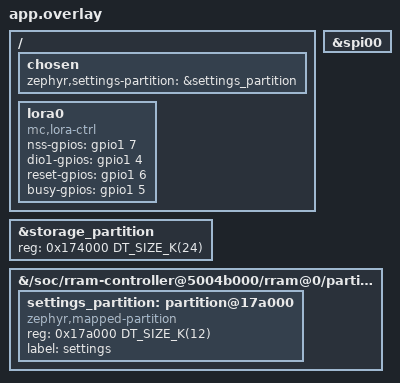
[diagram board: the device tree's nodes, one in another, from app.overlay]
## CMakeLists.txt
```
# Step 4e — full MeshCore companion (companion_radio MyMesh) on the Zephyr seams.
cmake_minimum_required(VERSION 3.20.0)
find_package(Zephyr REQUIRED HINTS $ENV{ZEPHYR_BASE})
project(mc_zephyr_companion)

get_filename_component(MC_ROOT "${CMAKE_CURRENT_SOURCE_DIR}/../.." ABSOLUTE)
set(CR       "${MC_ROOT}/examples/companion_radio")
set(ALFS     "${MC_ROOT}/arch/stm32/Adafruit_LittleFS_stm32/src")
set(RADIOLIB "$ENV{HOME}/Arduino/libraries/RadioLib/src")
set(CRYPTO   "$ENV{HOME}/Arduino/libraries/Crypto/src")
set(CAYENNE  "$ENV{HOME}/Arduino/libraries/CayenneLPP/src")
set(BASE64   "$ENV{HOME}/Arduino/libraries/base64/src")
set(RTCLIB   "$ENV{HOME}/Arduino/libraries/RTClib/src")
set(AJSON    "$ENV{HOME}/Arduino/libraries/ArduinoJson/src")
set(ED25519  "${MC_ROOT}/lib/ed25519")

# MeshCore core + helper set (mirrors the Arduino companion curation)
file(GLOB MC_CORE ${MC_ROOT}/src/*.cpp)
set(MC_HELPERS
  ${MC_ROOT}/src/helpers/BaseChatMesh.cpp
  ${MC_ROOT}/src/helpers/TransportKeyStore.cpp
  ${MC_ROOT}/src/helpers/IdentityStore.cpp
  ${MC_ROOT}/src/helpers/RegionMap.cpp
  ${MC_ROOT}/src/helpers/ClientACL.cpp
  ${MC_ROOT}/src/helpers/CommonCLI.cpp
  ${MC_ROOT}/src/helpers/AdvertDataHelpers.cpp
  ${MC_ROOT}/src/helpers/TxtDataHelpers.cpp
  ${MC_ROOT}/src/helpers/StaticPoolPacketManager.cpp
  ${MC_ROOT}/src/helpers/radiolib/RadioLibWrappers.cpp)

# companion firmware
set(MC_APP ${CR}/MyMesh.cpp ${CR}/DataStore.cpp)

# third-party (generic/non-Arduino mode for RadioLib)
file(GLOB_RECURSE RL_SOURCES ${RADIOLIB}/*.cpp)
list(FILTER RL_SOURCES EXCLUDE REGEX "/hal/Arduino/")
file(GLOB CRYPTO_SRC ${CRYPTO}/*.cpp ${CRYPTO}/*.c)
file(GLOB BASE64_SRC ${BASE64}/*.cpp)
# CayenneLPP + RTClib are shimmed in compat/ (header-only) — real libs pull STL/I2C.
file(GLOB ED_SRC ${ED25519}/*.c)
set(ALFS_SRC ${ALFS}/Adafruit_LittleFS.cpp ${ALFS}/Adafruit_LittleFS_File.cpp
             ${ALFS}/littlefs/lfs.c ${ALFS}/littlefs/lfs_util.c)

target_sources(app PRIVATE
  src/main.cpp src/target.cpp src/zephyr_internal_fs.cpp src/serial_ble_interface.cpp
  ${MC_CORE} ${MC_HELPERS} ${MC_APP}
  ${RL_SOURCES} ${CRYPTO_SRC} ${BASE64_SRC} ${ED_SRC} ${ALFS_SRC})

target_include_directories(app PRIVATE
  compat src ${MC_ROOT}/src ${CR} ${ALFS}
  ${RADIOLIB} ${CRYPTO} ${BASE64} ${ED25519})

target_compile_definitions(app PRIVATE
  NRF54_PLATFORM=1 RADIOLIB_GODMODE=1 MAX_GROUP_CHANNELS=8 MAX_CONTACTS=100 BLE_PIN_CODE=123456
  LFS_NO_ASSERT   # mount-fail (e.g. stale/repartitioned region) -> graceful format, not abort()
  # App TX-power slider max + firmware input check. Pin to the LR2021's absolute (sub-GHz LF)
  # PA ceiling of 22 dBm, INDEPENDENT of the band/boot default, so a 2.4 GHz build still allows
  # 22 once tuned back to sub-GHz. The real per-band limit (HF caps at +12) is enforced at the
  # radio layer by clamp_tx_for_band() in target.cpp. (Otherwise MAX would follow LORA_TX_POWER,
  # which MC_BAND_2G4 sets to 12 -> the app would be stuck at 12 even on 869 MHz.)
  MAX_LORA_TX_POWER=22)

# 2.4 GHz band: build with `-DMC_BAND_2G4=ON` (e.g. west build -- -DMC_BAND_2G4=ON) to boot on
# the LR2021's 2.4 GHz preset (target.h: 2450 MHz / 500 kHz / SF8 / CR5, TX clamped to +12 dBm)
# instead of the default 865 MHz sub-GHz. The app has no 2.4 GHz preset, so this is how to put
# the node on 2.4 GHz for the over-the-air RF test (the choice then persists in prefs).
option(MC_BAND_2G4 "Boot on the 2.4 GHz LoRa preset instead of sub-GHz" OFF)
# LoRa boot params must be global -D flags (mirroring platformio.ini), not header
# defines: core headers (e.g. RadioLibWrappers.h getSpreadingFactor) expand LORA_SF
# in translation units that never include target.h. Keep in sync with the presets
# documented in src/target.h.
if(MC_BAND_2G4)
  target_compile_definitions(app PRIVATE MC_BAND_2G4=1
    LORA_FREQ=2450.0f LORA_BW=500.0f LORA_SF=8 LORA_CR=5 LORA_TX_POWER=12)
  message(STATUS "MeshCore: building for 2.4 GHz band (2450 MHz / 500 kHz / SF8 / CR5)")
else()
  target_compile_definitions(app PRIVATE
    LORA_FREQ=869.618f LORA_BW=62.5f LORA_SF=8 LORA_CR=5 LORA_TX_POWER=22)
endif()
```

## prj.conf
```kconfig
# Step 4e — full MeshCore companion on Zephyr.
CONFIG_BT=y
CONFIG_BT_PERIPHERAL=y
CONFIG_BT_DEVICE_NAME="MeshCore"
CONFIG_BT_DEVICE_NAME_DYNAMIC=y
CONFIG_BT_DEVICE_NAME_MAX=40
CONFIG_BT_SMP=y
CONFIG_BT_BONDABLE=y
CONFIG_BT_FIXED_PASSKEY=y
# BT_MAX_PAIRED defaults to 1 (= BT_MAX_CONN). Phone A bonds -> the single bond slot fills;
# phone B then connects but its (MITM-enforced) pairing has no free slot and FAILS, so B can't
# reach the encryption-gated NUS -> "needs a hard reset to connect another device". Let a new
# pairing recycle the oldest bond instead. (Bonds are RAM-only here, BT_SETTINGS off, so this
# just means each new phone re-pairs cleanly.)
CONFIG_BT_KEYS_OVERWRITE_OLDEST=y
# NUS: we define our own encryption-gated NUS GATT service in serial_ble_interface.cpp
# (so the central drives pairing). Zephyr's built-in NUS is disabled to avoid a duplicate
# service with the same UUIDs.
# CONFIG_BT_ZEPHYR_NUS=y
CONFIG_BT_L2CAP_TX_MTU=247
CONFIG_BT_BUF_ACL_TX_SIZE=251
CONFIG_BT_BUF_ACL_RX_SIZE=251
# At boot the first BLE advertising event collides with the bring-up storm (LR2021 SPI
# init + LittleFS mount + mesh begin), so the SW-split controller's prepare callback runs
# tens of ms late on that one event. BT_CTLR_ASSERT_OVERHEAD_START (default y, a debug aid)
# turns that latency into a FATAL assert (lll_adv.c LL_ASSERT_OVERHEAD), which crashed the
# whole device -- taking the LoRa mesh down with it (no advert RX, looked like a reset loop).
# Disabling it restores the controller's designed behaviour: gracefully skip the delayed
# event (radio_disable + -ECANCELED) and keep running.
# NOTE: ASSERT_OVERHEAD_START lives in the controller's "Advanced features" menu, which is
# `visible if BT_CTLR_ADVANCED_FEATURES`. Without that gate enabled the prompt is hidden and
# a `=n` is silently ignored (symbol stays at its default y). Enable the gate (visibility
# only, no other behaviour change) so the override below actually takes effect.
CONFIG_BT_CTLR_ADVANCED_FEATURES=y
CONFIG_BT_CTLR_ASSERT_OVERHEAD_START=n

CONFIG_FLASH=y
CONFIG_FLASH_MAP=y
# RRAM is byte-alterable and writes (no long erase like NOR flash). The flash driver
# otherwise defaults to RADIO_SYNC_TICKER (because BT_LL_SW_SPLIT), which schedules every
# write into BLE idle timeslots. While connected that dribbles a savePrefs() out one tiny
# window per connection event => a fixed 24s per settings write. Disable radio sync: RRAM
# writes are short enough to run synchronously without disturbing the radio (also bumps the
# RRAM write-buffer 1 -> 32, fewer commits).
CONFIG_SOC_FLASH_NRF_RADIO_SYNC_NONE=y

# Bond persistence DISABLED: on the vanilla open-source controller it broke bonded
# reconnect (phone re-pairs on every reconnect -> disconnect loop) and earlier overflowed
# the bond-save stack. Each connect is a fresh pair (the known-good Android-working flow).
# Robust persistence needs NCS + Nordic SoftDevice Controller (handles bonded-RPA reconnect).
# CONFIG_BT_SETTINGS=y
# CONFIG_SETTINGS=y
# CONFIG_NVS=y
# CONFIG_SETTINGS_NVS=y
# (stacks kept harmless, headroom for the BT/workqueue paths)
CONFIG_BT_RX_STACK_SIZE=4096
CONFIG_SYSTEM_WORKQUEUE_STACK_SIZE=4096

CONFIG_GPIO=y
CONFIG_SPI=y
CONFIG_CPP=y
CONFIG_STD_CPP17=y
CONFIG_CPP_EXCEPTIONS=n
CONFIG_PRINTK=y
CONFIG_CBPRINTF_FP_SUPPORT=y
CONFIG_MAIN_STACK_SIZE=16384
CONFIG_HEAP_MEM_POOL_SIZE=16384
CONFIG_FPU=y
CONFIG_REBOOT=y
CONFIG_ENTROPY_GENERATOR=y
```

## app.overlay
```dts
/*
 * LR2021 wiring on the XIAO nRF54L15 (matches variants/xiao_nrf54l15/target.h):
 *   SPI  = spi00 (xiao_spi): SCK=P2.1(D8) MOSI=P2.2(D10) MISO=P2.4(D9)
 *   NSS  = P1.7 (D3)   DIO1 = P1.4 (D0)   RESET = P1.6 (D2)   BUSY = P1.5 (D1)
 *
 * RadioLib drives NSS itself (digitalWrite), so the SPI controller is used WITHOUT
 * a hardware CS. The four control pins are plain GPIOs (flags=0 / active-high; the
 * HAL uses raw ops so RadioLib's LOW/HIGH map to physical levels, as on Arduino).
 */
&spi00 {
	status = "okay";
};

/*
 * Split the 36 KB RRAM storage region (0x174000..0x17D000): MeshCore's LittleFS keeps
 * 24 KB; a 12 KB NVS settings partition holds BLE bonds (CONFIG_BT_SETTINGS) so the app
 * doesn't have to re-pair after every reboot.
 */
&storage_partition {
	reg = <0x174000 DT_SIZE_K(24)>;
};

/* add the settings partition as a sibling under the existing fixed-partitions node */
&{/soc/rram-controller@5004b000/rram@0/partitions} {
	settings_partition: partition@17a000 {
		compatible = "zephyr,mapped-partition";
		reg = <0x17a000 DT_SIZE_K(12)>;
		label = "settings";
	};
};

/ {
	chosen {
		zephyr,settings-partition = &settings_partition;
	};

	lora0: lora0 {
		compatible = "mc,lora-ctrl";
		nss-gpios   = <&gpio1 7 0>;
		dio1-gpios  = <&gpio1 4 0>;
		reset-gpios = <&gpio1 6 0>;
		busy-gpios  = <&gpio1 5 0>;
	};
};
```

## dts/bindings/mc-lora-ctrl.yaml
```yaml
description: |
  LR2021 control GPIOs driven directly by RadioLib (NSS/DIO1/RESET/BUSY).
  Not a real device node; just a holder so GPIO_DT_SPEC_GET generates the
  pin/flags cell macros for these phandle-array properties.

compatible: "mc,lora-ctrl"

properties:
  nss-gpios:
    type: phandle-array
    required: true
  dio1-gpios:
    type: phandle-array
    required: true
  reset-gpios:
    type: phandle-array
    required: true
  busy-gpios:
    type: phandle-array
    required: true
```

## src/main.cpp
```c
/*
 * Step 4e: the full MeshCore companion on Zephyr. Wires companion_radio's MyMesh +
 * DataStore onto the proven Zephyr seams: radio (target.cpp / RadioLib+ZephyrHal),
 * filesystem (InternalFS / flash_area), and serial = the bonded bt_nus SerialBLEInterface.
 * The phone app pairs (level 4, fixed PIN), then talks the companion protocol over NUS.
 */
#include <zephyr/kernel.h>
#include <zephyr/sys/printk.h>
#include <string.h>
#include <Arduino.h>
#include <target.h>
#include <helpers/nrf54/InternalFileSystem.h>
#include <helpers/SimpleMeshTables.h>
#include "serial_ble_interface.h"
#include "MyMesh.h"   /* examples/companion_radio (on the include path) */

SerialShim Serial;

StdRNG fast_rng;
SimpleMeshTables tables;
DataStore store(InternalFS, rtc_clock);
MyMesh the_mesh(radio_driver, fast_rng, rtc_clock, tables, store);

int main(void)
{
	printk("\n=== MeshCore companion on Zephyr (board=%s) ===\n", CONFIG_BOARD);

	board.begin();
	if (!radio_init()) { printk("radio_init FAILED\n"); return 0; }
	fast_rng.begin(radio_get_rng_seed());
	if (!InternalFS.begin()) { printk("InternalFS FAILED\n"); return 0; }
	store.begin();
	the_mesh.begin(false);   /* no display (loads prefs from /new_prefs) */

	/* DEBUG: did the node name survive the last power cycle? On a cold boot this should show
	 * the previously-set name and exists=1; if it shows the default name / exists=0 the prefs
	 * file was lost (reformat or never persisted). Paired with the "FS: mounted OK/FAILED" line. */
	printk("PREFS: cold boot -> /new_prefs exists=%d, node_name='%s'\n",
	       InternalFS.exists("/new_prefs"), the_mesh.getNodePrefs()->node_name);

	char name[48];
	snprintf(name, sizeof(name), "%s%s", BLE_NAME_PREFIX, the_mesh.getNodePrefs()->node_name);
	ble.begin(name, the_mesh.getBLEPin());
	the_mesh.startInterface(ble);
	printk("companion up: '%s' pin %lu — connect from the MeshCore app\n",
	       name, (unsigned long)the_mesh.getBLEPin());

	while (1) {
		the_mesh.loop();
		rtc_clock.tick();
		sensors.loop();

		/* A rename from the app (CMD_SET_ADVERT_NAME) only updates prefs; push it to BLE so
		 * the advertised/GAP name follows without a reboot. */
		char cur[48];
		snprintf(cur, sizeof(cur), "%s%s", BLE_NAME_PREFIX, the_mesh.getNodePrefs()->node_name);
		if (strcmp(cur, name) != 0) {
			strcpy(name, cur);
			ble.setDeviceName(name);
			/* DEBUG: confirm the rename reached the FS (savePrefs ran in the CMD handler).
			 * exists=1 means /new_prefs was (re)written; if it's still 0 the save never landed. */
			printk("PREFS: rename -> '%s', /new_prefs exists=%d\n",
			       the_mesh.getNodePrefs()->node_name, InternalFS.exists("/new_prefs"));
		}

		k_msleep(1);   /* snappy serial/radio polling for the app's frame bursts */
	}
	return 0;
}
```

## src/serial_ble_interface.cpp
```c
#include "serial_ble_interface.h"
#include <zephyr/sys/printk.h>
#include <zephyr/bluetooth/bluetooth.h>
#include <zephyr/bluetooth/conn.h>
#include <zephyr/bluetooth/gatt.h>
#include <zephyr/bluetooth/uuid.h>
#include <zephyr/settings/settings.h>
#include <string.h>

SerialBLEInterface ble;

#ifndef BLE_DBG
#define BLE_DBG(...) printk("BLE: " __VA_ARGS__)
#endif

#ifndef MC_BLE_VERBOSE
#define MC_BLE_VERBOSE 1     /* dump every companion frame in/out */
#endif

#if MC_BLE_VERBOSE
static void mc_dump(const char *dir, const uint8_t *b, uint16_t len)
{
	printk("[%8lld] %s code=%-3u len=%-3u :", (long long)k_uptime_get(), dir, len ? b[0] : 0, len);
	for (uint16_t i = 0; i < len && i < 28; i++) printk(" %02x", b[i]);
	printk("%s\n", len > 28 ? " ..." : "");
}
#else
#define mc_dump(d, b, l)
#endif

/* advertising payload: name + NUS 128-bit UUID (so the MeshCore app finds us).
 * g_ad[1] (the scan-list name) is rewritten at begin() from the runtime node name;
 * CONFIG_BT_DEVICE_NAME is only a placeholder. bt_set_name() sets the GAP Device Name
 * *characteristic* but NOT this advertising payload, so without the rewrite the node
 * always advertised the static "MeshCore" regardless of the configured node name. */
static char g_adv_name[27];   /* 31B adv - 3B flags - 2B AD header => 26 name chars + NUL */
static struct bt_data g_ad[] = {
	BT_DATA_BYTES(BT_DATA_FLAGS, (BT_LE_AD_GENERAL | BT_LE_AD_NO_BREDR)),
	BT_DATA(BT_DATA_NAME_COMPLETE, CONFIG_BT_DEVICE_NAME, sizeof(CONFIG_BT_DEVICE_NAME) - 1),
};
static const struct bt_data g_sd[] = {
	BT_DATA_BYTES(BT_DATA_UUID128_ALL,
		BT_UUID_128_ENCODE(0x6E400001, 0xB5A3, 0xF393, 0xE0A9, 0xE50E24DCCA9E)),
};

/* custom Nordic-UART service, ENCRYPTION-GATED so the *central* drives pairing
 * Zephyr's stock bt_nus characteristics are PERM_NONE, which forced us to send a peripheral
 * SMP Security Request on connect; iOS/Windows respond to that by pairing then dropping &
 * reconnecting. Gating the RX-write and the TX CCC on *authenticated* encryption makes the
 * central initiate MITM (passkey) pairing on first access and stay on the same link. */
static struct bt_uuid_128 nus_srv_uuid = BT_UUID_INIT_128(
	BT_UUID_128_ENCODE(0x6E400001, 0xB5A3, 0xF393, 0xE0A9, 0xE50E24DCCA9E));
static struct bt_uuid_128 nus_tx_uuid = BT_UUID_INIT_128(   /* notify: NODE->APP */
	BT_UUID_128_ENCODE(0x6E400003, 0xB5A3, 0xF393, 0xE0A9, 0xE50E24DCCA9E));
static struct bt_uuid_128 nus_rx_uuid = BT_UUID_INIT_128(   /* write:  APP->NODE */
	BT_UUID_128_ENCODE(0x6E400002, 0xB5A3, 0xF393, 0xE0A9, 0xE50E24DCCA9E));

static ssize_t nus_rx_write(struct bt_conn *conn, const struct bt_gatt_attr *attr,
			    const void *buf, uint16_t len, uint16_t offset, uint8_t flags)
{
	(void)conn; (void)attr; (void)offset; (void)flags;
	ble._onRx(buf, len);
	return len;
}
static void nus_tx_ccc_changed(const struct bt_gatt_attr *attr, uint16_t value) { (void)attr; (void)value; }

/* attrs[0]=svc [1]=TX chrc [2]=TX value [3]=CCC [4]=RX chrc [5]=RX value;
 * notify on attrs[1] (mirrors Zephyr's bt_nus_send). */
BT_GATT_SERVICE_DEFINE(nus_svc,
	BT_GATT_PRIMARY_SERVICE(&nus_srv_uuid),
	BT_GATT_CHARACTERISTIC(&nus_tx_uuid.uuid, BT_GATT_CHRC_NOTIFY,
			       BT_GATT_PERM_NONE, NULL, NULL, NULL),
	BT_GATT_CCC(nus_tx_ccc_changed, BT_GATT_PERM_READ | BT_GATT_PERM_WRITE_AUTHEN),
	BT_GATT_CHARACTERISTIC(&nus_rx_uuid.uuid,
			       BT_GATT_CHRC_WRITE | BT_GATT_CHRC_WRITE_WITHOUT_RESP,
			       BT_GATT_PERM_WRITE_AUTHEN, NULL, nus_rx_write, NULL),
);

/* C BLE callbacks bridging to the single `ble` instance */
static void cb_connected(struct bt_conn *conn, uint8_t err)
{
	if (err) { BLE_DBG("connect failed 0x%02x\n", err); return; }
	BLE_DBG("connected\n");
	ble._onConnect(conn);
	/* Do NOT initiate security here. The NUS characteristics are gated on authenticated
	 * encryption, so the CENTRAL triggers MITM pairing on first access and keeps the link.
	 * A peripheral-initiated Security Request is what made iOS/Windows pair-then-reconnect. */
}
static void cb_disconnected(struct bt_conn *conn, uint8_t reason)
{
	BLE_DBG("disconnected 0x%02x\n", reason);
	ble._onDisconnect(conn);
}
static void cb_security_changed(struct bt_conn *conn, bt_security_t level, enum bt_security_err err)
{
	BLE_DBG("security level %d err %d\n", level, err);
	ble._onSecured(conn, err == BT_SECURITY_ERR_SUCCESS && level >= BT_SECURITY_L2);
}
BT_CONN_CB_DEFINE(conn_cbs) = {
	.connected = cb_connected,
	.disconnected = cb_disconnected,
	.security_changed = cb_security_changed,
};

static void auth_passkey_display(struct bt_conn *conn, unsigned int passkey)
{
	BLE_DBG(">>> enter PASSKEY on phone: %06u <<<\n", passkey);
}
static void auth_cancel(struct bt_conn *conn) { BLE_DBG("pairing cancelled\n"); }
static struct bt_conn_auth_cb auth_cb = {
	.passkey_display = auth_passkey_display,
	.cancel = auth_cancel,
};
static void pairing_complete(struct bt_conn *conn, bool bonded)
{
	BLE_DBG("*** PAIRING COMPLETE bonded=%d ***\n", bonded);
}
static void pairing_failed(struct bt_conn *conn, enum bt_security_err reason)
{
	BLE_DBG("!!! PAIRING FAILED reason=%d !!!\n", reason);
}
static struct bt_conn_auth_info_cb auth_info_cb = {
	.pairing_complete = pairing_complete,
	.pairing_failed = pairing_failed,
};

/* --- SerialBLEInterface impl --- */
void SerialBLEInterface::begin(const char *device_name, uint32_t pin_code)
{
	k_mutex_init(&_lock);
	int err = bt_enable(NULL);
	if (err) { BLE_DBG("bt_enable %d\n", err); return; }

	if (IS_ENABLED(CONFIG_SETTINGS)) {
		settings_load();   /* restore bonds saved by CONFIG_BT_SETTINGS */
	}
	bt_passkey_set(pin_code);
	bt_conn_auth_cb_register(&auth_cb);
	bt_conn_auth_info_cb_register(&auth_info_cb);
	setDeviceName(device_name);
	BLE_DBG("init done; advertising as '%s' pin %06u\n", bt_get_name(), pin_code);
}

void SerialBLEInterface::setDeviceName(const char *device_name)
{
	if (!device_name || !*device_name) return;
	bt_set_name(device_name);   /* GAP Device Name characteristic (read after connect) */
	/* Mirror the name into the advertising payload (the scan-list name the phone shows),
	 * truncating to the 26-char adv budget. Without this the scan list always read
	 * "MeshCore", and a runtime rename never reached the advertisement at all. The new
	 * g_ad[] is picked up by the next mc_start_adv(); if idle, refresh the live advertisement now. */
	size_t n = strlen(device_name);
	bool shortened = n > sizeof(g_adv_name) - 1;
	if (shortened) n = sizeof(g_adv_name) - 1;
	memcpy(g_adv_name, device_name, n);
	g_adv_name[n] = '\0';
	g_ad[1].type = shortened ? BT_DATA_NAME_SHORTENED : BT_DATA_NAME_COMPLETE;
	g_ad[1].data = (const uint8_t *)g_adv_name;
	g_ad[1].data_len = n;
	BLE_DBG("device name set to '%s'\n", g_adv_name);
	if (_enabled && _conn == nullptr && _advertising) {
		bt_le_adv_update_data(g_ad, ARRAY_SIZE(g_ad), g_sd, ARRAY_SIZE(g_sd));
	}
}

static int mc_start_adv(void)
{
	return bt_le_adv_start(BT_LE_ADV_PARAM(BT_LE_ADV_OPT_CONN,
					       BT_GAP_ADV_FAST_INT_MIN_2,
					       BT_GAP_ADV_FAST_INT_MAX_2, NULL),
			       g_ad, ARRAY_SIZE(g_ad), g_sd, ARRAY_SIZE(g_sd));
}

void SerialBLEInterface::enable()
{
	if (_enabled) return;
	_enabled = true;
	int err = mc_start_adv();
	_advertising = (err == 0);
	BLE_DBG("adv start -> %d\n", err);
}

void SerialBLEInterface::disable()
{
	_enabled = false;
	bt_le_adv_stop();
	if (_conn) bt_conn_disconnect((struct bt_conn *)_conn, BT_HCI_ERR_REMOTE_USER_TERM_CONN);
}

bool SerialBLEInterface::isConnected() const { return _conn != nullptr && _secured; }
bool SerialBLEInterface::isWriteBusy() const { return _send_len >= (QSZ * 2 / 3); }

void SerialBLEInterface::_onConnect(void *conn)
{
	_conn = bt_conn_ref((struct bt_conn *)conn);
	_secured = false;
	_advertising = false;   /* Zephyr stops connectable adv once a connection forms */
	_send_len = 0;
	k_mutex_lock(&_lock, K_FOREVER); _recv_len = 0; k_mutex_unlock(&_lock);
}
void SerialBLEInterface::_onDisconnect(void *conn)
{
	if (_conn) { bt_conn_unref((struct bt_conn *)_conn); _conn = nullptr; }
	_secured = false;
	/* re-advertise is handled in checkRecvFrame() (main thread) avoid BT calls here */
}
void SerialBLEInterface::_onSecured(void *conn, bool ok)
{
	(void)conn;
	_secured = ok;
	/* NOTE: previously requested a conn interval here for Android latency, but an
	 * unsolicited param update right after pairing stalls iOS .
	 * Let the central manage connection parameters. */
}

void SerialBLEInterface::_onRx(const void *data, uint16_t len)
{
	if (len == 0 || len > MAX_FRAME_SIZE) return;
	mc_dump("APP->NODE", (const uint8_t *)data, len);
	k_mutex_lock(&_lock, K_FOREVER);
	if (_recv_len < QSZ) {
		_recv[_recv_len].len = len;
		memcpy(_recv[_recv_len].buf, data, len);
		_recv_len++;
	} else {
		printk("BLE: RX queue FULL, dropping frame\n");
	}
	k_mutex_unlock(&_lock);
}

void SerialBLEInterface::shiftSend()
{
	if (_send_len > 0) {
		_send_len--;
		for (uint8_t i = 0; i < _send_len; i++) _send[i] = _send[i + 1];
	}
}

size_t SerialBLEInterface::writeFrame(const uint8_t src[], size_t len)
{
	if (len == 0 || len > MAX_FRAME_SIZE) return 0;
	if (!isConnected() || _send_len >= QSZ) return 0;
	_send[_send_len].len = len;
	memcpy(_send[_send_len].buf, src, len);
	_send_len++;
	return len;
}

size_t SerialBLEInterface::checkRecvFrame(uint8_t dest[])
{
	/* drain queued TX frames over NUS. Push as many as the controller will take this
	 * call (multiple notifications per connection event) instead of one per loop tick;
	 * stop on -ENOMEM (buffers full, retry next call). Speeds up multi-frame answers
	 * (settings/contacts) without touching connection parameters. */
	if (_send_len > 0) {
		if (!isConnected()) {
			_send_len = 0;
		} else {
			while (_send_len > 0) {
				int rc = bt_gatt_notify((struct bt_conn *)_conn, &nus_svc.attrs[1], _send[0].buf, _send[0].len);
				if (rc == 0) { mc_dump("NODE->APP", _send[0].buf, _send[0].len); shiftSend(); }
				else if (rc == -ENOTCONN) { shiftSend(); break; }   /* gone */
				else { printk("BLE: bt_nus_send rc=%d (retry)\n", rc); break; }  /* -ENOMEM: buffers full */
			}
		}
	}
	/* return one received frame */
	size_t out = 0;
	k_mutex_lock(&_lock, K_FOREVER);
	if (_recv_len > 0) {
		out = _recv[0].len;
		memcpy(dest, _recv[0].buf, out);
		_recv_len--;
		for (uint8_t i = 0; i < _recv_len; i++) _recv[i] = _recv[i + 1];
	}
	k_mutex_unlock(&_lock);

	/* re-advertise after a disconnect so the app can reconnect without a board reset */
	if (_enabled && _conn == nullptr && !_advertising) {
		unsigned long now = k_uptime_get();
		if (now - _last_adv_try > 500) {        /* throttle retries */
			_last_adv_try = now;
			int rc = mc_start_adv();
			if (rc == 0) {
				_advertising = true;
				BLE_DBG("re-advertising after disconnect\n");
			} else {
				BLE_DBG("re-advertise FAILED rc=%d (will retry)\n", rc);
			}
		}
	}
	return out;
}
```

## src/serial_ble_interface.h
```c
/*
 * Zephyr SerialBLEInterface: MeshCore's BaseSerialInterface over the Zephyr NUS
 * (bt_nus) + the step-2 bonded pairing (LE SC + MITM + fixed PIN). This is the
 * serial seam the companion role will use; the companion-protocol bytes ride
 * the encrypted, bonded NUS link that the bare-metal core could never establish.
 */
#pragma once
#include <Arduino.h>
#include <helpers/BaseSerialInterface.h>
#include <zephyr/kernel.h>

class SerialBLEInterface : public BaseSerialInterface {
  public:
	/* prefix+name -> advertised name; pin_code = fixed BLE passkey. */
	void begin(const char *device_name, uint32_t pin_code);

	/* Apply (or re-apply at runtime) the BLE name: sets the GAP Device Name characteristic
	 * AND the advertising payload, so a rename takes effect on the next advertise without a
	 * reboot. Safe to call while connected (the new name is used on the next re-advertise). */
	void setDeviceName(const char *device_name);

	void enable() override;
	void disable() override;
	bool isEnabled() const override { return _enabled; }
	bool isConnected() const override;
	bool isWriteBusy() const override;
	size_t writeFrame(const uint8_t src[], size_t len) override;
	size_t checkRecvFrame(uint8_t dest[]) override;

	/* invoked from the C BLE callbacks (see .cpp) */
	void _onConnect(void *conn);
	void _onDisconnect(void *conn);
	void _onSecured(void *conn, bool ok);
	void _onRx(const void *data, uint16_t len);

  private:
	struct Frame {
		uint16_t len;
		uint8_t buf[MAX_FRAME_SIZE];
	};
	static const uint8_t QSZ = 12;

	Frame _send[QSZ];
	uint8_t _send_len = 0;          /* main-thread only */
	Frame _recv[QSZ];
	uint8_t _recv_len = 0;          /* filled in BT ctx, read in main -> guarded by _lock */
	struct k_mutex _lock;

	void *_conn = nullptr;          /* struct bt_conn* */
	bool _enabled = false;
	bool _secured = false;
	bool _advertising = false;
	unsigned long _last_adv_try = 0;

	void shiftSend();
};

extern SerialBLEInterface ble;
```

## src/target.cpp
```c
#include "target.h"
#include "zephyr_radiolib_hal.h"
/* Chip quirks (header-CRC standby, RX max-length re-assert) and the mesh wrapper
 * (standby-before-re-arm, RSSI hooks) are shared with the bare-metal variant via
 * CustomLR2021 / CustomLR2021Wrapper — single source for the LR2021 fixes. */
#include <helpers/radiolib/CustomLR2021Wrapper.h>
#include <zephyr/sys/reboot.h>

static ZephyrHal hal;

static Module s_mod(&hal, LR_PIN_NSS, LR_PIN_DIO1, LR_PIN_RESET, LR_PIN_BUSY);
static CustomLR2021 s_lora(&s_mod);

ZBoard board;   /* defined before the radio wrapper that references it */

static CustomLR2021Wrapper s_radio(s_lora, board);

RadioLibWrapper &radio_driver = s_radio;
VolatileRTCClock rtc_clock;
SensorManager    sensors;

mesh::LocalIdentity radio_new_identity()
{
	RadioNoiseListener rng(s_lora);
	return mesh::LocalIdentity(&rng);   /* new identity from LoRa RSSI noise */
}

void ZBoard::reboot() { sys_reboot(SYS_REBOOT_COLD); }

#define MC_HF_CUTOFF_MHZ  1500.0f

static float  s_freq    = LORA_FREQ;
static int8_t s_req_dbm = LORA_TX_POWER;   /* last app-requested power, pre-clamp */

static int8_t clamp_tx_for_band(float freq, int8_t dbm)
{
	if (freq > MC_HF_CUTOFF_MHZ)                       /* 2.4 GHz HF PA: -19..+12 */
		return dbm > 12 ? 12 : (dbm < -19 ? -19 : dbm);
	return dbm > 22 ? 22 : (dbm < -9 ? -9 : dbm);     /* sub-GHz LF PA: -9..+22 */
}


static bool radio_bringup(float freq, float bw, uint8_t sf, uint8_t cr)
{
	for (int attempt = 0; attempt < 8; attempt++) {

		int16_t st = s_lora.begin(freq, bw, sf, cr,
					  RADIOLIB_LR2021_LORA_SYNC_WORD_PRIVATE,
					  clamp_tx_for_band(freq, s_req_dbm), 16, /*tcxoVoltage=*/0.0f);
		if (st == RADIOLIB_ERR_NONE) {
			/* match CustomLR2021's proven config: explicit header, CRC, RX boosted gain */
			s_lora.explicitHeader();
			s_lora.setCRC(2);
			s_lora.setRxBoostedGainMode(LR2021_RX_BOOST_LEVEL);
			int16_t rx = s_lora.startReceive();      /* the operation that fails on a bad boot */
			if (rx == RADIOLIB_ERR_NONE) {
				s_lora.standby();                /* idle; the wrapper arms RX in its loop */
				s_freq = freq;
				if (attempt) printk("radio: RX ok after %d retr%s\n",
						    attempt, attempt == 1 ? "y" : "ies");
				return true;
			}
			printk("radio: begin ok but RX arm failed (%d), resetting\n", rx);
		} else {
			printk("radio: begin failed (%d), resetting\n", st);
		}
		s_lora.reset();        /* full chip reset, then retry the whole bring-up */
		k_msleep(50);
	}
	return false;
}

bool radio_init()
{
	s_lora.setIrqDio(LR2021_IRQ_DIO);
	s_freq = LORA_FREQ;
	s_req_dbm = LORA_TX_POWER;
	if (!radio_bringup(LORA_FREQ, LORA_BW, LORA_SF, LORA_CR)) return false;
	s_radio.begin();
	return true;
}

uint32_t radio_get_rng_seed() { return s_lora.random(0x7FFFFFFF); }

void radio_set_params(float freq, float bw, uint8_t sf, uint8_t cr)
{

	bool band_changed = (freq > MC_HF_CUTOFF_MHZ) != (s_freq > MC_HF_CUTOFF_MHZ);
	s_lora.standby();
	int16_t st = s_lora.setFrequency(freq);     /* recalibrates the front-end for the band */
	if (st == RADIOLIB_ERR_NONE) st = s_lora.setBandwidth(bw);
	if (st == RADIOLIB_ERR_NONE) st = s_lora.setSpreadingFactor(sf);
	if (st == RADIOLIB_ERR_NONE) st = s_lora.setCodingRate(cr);
	s_freq = freq;
	if (band_changed) s_lora.setOutputPower(clamp_tx_for_band(freq, s_req_dbm));
	s_radio.begin();   /* reset wrapper -> dispatcher re-arms RX (startReceive) on the new config */
	if (st != RADIOLIB_ERR_NONE) {
		printk("radio_set_params: apply error %d for %u kHz bw=%u kHz sf%u cr%u\n",
		       st, (unsigned)(freq * 1000.0f), (unsigned)(bw * 1000.0f), sf, cr);
	} else {
		printk("radio_set_params: now on %u kHz bw=%u kHz sf%u cr%u\n",
		       (unsigned)(freq * 1000.0f), (unsigned)(bw * 1000.0f), sf, cr);
	}
}

void radio_set_tx_power(int8_t dbm)
{
	s_req_dbm = dbm;
	s_lora.setOutputPower(clamp_tx_for_band(s_freq, dbm));
}
```

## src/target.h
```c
/*
 * Zephyr variant glue for the XIAO nRF54L15 + LR2021: the target.h MeshCore's
 * companion expects (board / radio_driver / rtc_clock / sensors + radio_* funcs +
 * LoRa/BLE config). The concrete radio seam (RadioLib LR2021 + ZephyrHal) lives in
 * target.cpp so its headers (with static-member defs) aren't multiply-included.
 */
#pragma once
#include <Arduino.h>
#include <Mesh.h>
#include <helpers/ArduinoHelpers.h>
#include <helpers/SensorManager.h>
#include <helpers/radiolib/RadioLibWrappers.h>   /* RadioLibWrapper API MyMesh uses */

/* 2.4 GHz preset (LR2021 is dual-band)
 * The RadioLib driver auto-switches to the HF path for any frequency in 2400-2500 MHz;
 * target.cpp clamps TX power to the HF PA max of +12 dBm. NOTE: MeshCore's companion caps
 * bandwidth at 500 kHz, so 812/406 (which the chip supports) are rejected by SET_RADIO_PARAMS. */
#define LORA_FREQ_2G4      2450.0f
#define LORA_BW_2G4        500.0f   /* kHz */
#define LORA_SF_2G4        8
#define LORA_CR_2G4        5
#define LORA_TX_POWER_2G4  12       /* dBm — HF PA maximum */

/* LoRa boot defaults: MeshCore EU sub-GHz canon, unless the build defines MC_BAND_2G4 (see
 * CMakeLists), which boots straight onto the 2.4 GHz preset above. 865 MHz stays the normal
 * build; a 2G4 build needs no app interaction (and the choice persists in prefs). The app
 * has no 2.4 GHz preset of its own, presets are app-side and sub-GHz only, so this flag is
 * the practical way to put the node on 2.4 GHz for the RF test. */
/* NOTE: the real build-time source of these is CMakeLists.txt (global -D flags,
 * mirroring platformio.ini): core headers such as RadioLibWrappers.h expand
 * LORA_SF in translation units that never include this file. The block below is
 * only a fallback for tooling (clangd/IDE) parsing this header standalone. */
#ifdef MC_BAND_2G4
  #ifndef LORA_FREQ
  #define LORA_FREQ      LORA_FREQ_2G4
  #endif
  #ifndef LORA_BW
  #define LORA_BW        LORA_BW_2G4
  #endif
  #ifndef LORA_SF
  #define LORA_SF        LORA_SF_2G4
  #endif
  #ifndef LORA_CR
  #define LORA_CR        LORA_CR_2G4
  #endif
  #ifndef LORA_TX_POWER
  #define LORA_TX_POWER  LORA_TX_POWER_2G4
  #endif
#else
  #ifndef LORA_FREQ
  #define LORA_FREQ      869.618f
  #endif
  #ifndef LORA_BW
  #define LORA_BW        62.5f
  #endif
  #ifndef LORA_SF
  #define LORA_SF        8
  #endif
  #ifndef LORA_CR
  #define LORA_CR        5
  #endif
  #ifndef LORA_TX_POWER
  #define LORA_TX_POWER  22
  #endif
#endif

/* BLE companion */
#ifndef BLE_PIN_CODE
#define BLE_PIN_CODE   123456
#endif
#ifndef BLE_NAME_PREFIX
#define BLE_NAME_PREFIX "MeshCore-"
#endif

class ZBoard : public mesh::MainBoard {
  public:
	void begin() {}
	uint16_t getBattMilliVolts() override { return 0; }
	const char *getManufacturerName() const override { return "XIAO nRF54L15"; }
	void reboot() override;          /* sys_reboot — defined in target.cpp */
	uint8_t getStartupReason() const override { return _reason; }
	uint8_t _reason = 0;
};

extern ZBoard            board;
extern RadioLibWrapper  &radio_driver;   /* concrete LR2021 wrapper bound in target.cpp */
extern VolatileRTCClock  rtc_clock;
extern SensorManager     sensors;

bool radio_init();
uint32_t radio_get_rng_seed();
void radio_set_params(float freq, float bw, uint8_t sf, uint8_t cr);
void radio_set_tx_power(int8_t dbm);
mesh::LocalIdentity radio_new_identity();
```

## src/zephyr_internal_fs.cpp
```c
/*
 * Zephyr backing for MeshCore's nrf54 InternalFileSystem (the header MeshCore's
 * NRF54_PLATFORM branch includes). Same Adafruit_LittleFS class, lfs block device
 * over Zephyr flash_area on `storage_partition` (validated in zephyr-port/06_fs).
 * Compile THIS instead of the bare-metal RRAMC InternalFileSystem.cpp.
 */
#include <helpers/nrf54/InternalFileSystem.h>
#include <zephyr/storage/flash_map.h>
#include <zephyr/sys/printk.h>
#include <string.h>

#define FS_PARTITION  storage_partition

#define BS            2048            /* littlefs logical block (== read/prog size) */
#define BC            12              /* 24 KB storage_partition / 2048 */

static const struct flash_area *g_fa = NULL;

static int _fa_read(const struct lfs_config *c, lfs_block_t b, lfs_off_t o, void *buf, lfs_size_t sz) {
	(void)c; return flash_area_read(g_fa, (off_t)b * BS + o, buf, sz) == 0 ? LFS_ERR_OK : LFS_ERR_IO;
}
static int _fa_prog(const struct lfs_config *c, lfs_block_t b, lfs_off_t o, const void *buf, lfs_size_t sz) {
	(void)c; return flash_area_write(g_fa, (off_t)b * BS + o, buf, sz) == 0 ? LFS_ERR_OK : LFS_ERR_IO;
}
static int _fa_erase(const struct lfs_config *c, lfs_block_t b) {
	(void)c; (void)b;

	return LFS_ERR_OK;
}
static int _fa_sync(const struct lfs_config *c) { (void)c; return LFS_ERR_OK; }

struct lfs_config _InternalFSConfig = {
	.context = NULL,
	.read  = _fa_read, .prog = _fa_prog, .erase = _fa_erase, .sync = _fa_sync,
	.read_size = BS, .prog_size = BS, .block_size = BS, .block_count = BC, .lookahead = 128,
	.read_buffer = NULL, .prog_buffer = NULL, .lookahead_buffer = NULL, .file_buffer = NULL
};

InternalFileSystem InternalFS;
InternalFileSystem::InternalFileSystem(void) : Adafruit_LittleFS(&_InternalFSConfig) {}

bool InternalFileSystem::begin(void) {
	if (g_fa == NULL && flash_area_open(FIXED_PARTITION_ID(FS_PARTITION), &g_fa) != 0) {
		printk("FS: flash_area_open FAILED\n");
		return false;
	}
	if (!Adafruit_LittleFS::begin()) {
		printk("FS: mount FAILED -> reformatting (any persisted prefs/contacts are lost)\n");
		this->format();
		if (!Adafruit_LittleFS::begin()) { printk("FS: format+remount FAILED\n"); return false; }
	} else {
		printk("FS: mounted OK (persisted data intact)\n");
	}
	return true;
}
```

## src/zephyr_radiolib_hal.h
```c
/*
 * Minimal RadioLibHal for Zephyr (XIAO nRF54L15). Maps RadioLib's opaque pin ids
 * to gpio_dt_spec from the `lora0` devicetree node, and SPI to the spi00 controller
 * (no hardware CS, RadioLib drives NSS via digitalWrite). Raw GPIO ops keep
 * RadioLib's Arduino LOW/HIGH == physical-level semantics.
 *
 * Pin ids passed to Module(hal, cs, irq, rst, gpio):  NSS=0 DIO1=1 RESET=2 BUSY=3.
 */
#pragma once
#include <zephyr/kernel.h>
#include <zephyr/drivers/gpio.h>
#include <zephyr/drivers/spi.h>
#include <RadioLib.h>

#define LR_PIN_NSS   0
#define LR_PIN_DIO1  1
#define LR_PIN_RESET 2
#define LR_PIN_BUSY  3
#define LR_PIN_COUNT 4

#define LORA0_NODE DT_NODELABEL(lora0)
#define SPI0_NODE  DT_NODELABEL(spi00)

class ZephyrHal : public RadioLibHal {
  public:
    /* GPIO modes / levels / edges — opaque tokens RadioLib hands back to us. */
    ZephyrHal()
      : RadioLibHal(/*INPUT*/0, /*OUTPUT*/1, /*LOW*/0, /*HIGH*/1, /*RISING*/1, /*FALLING*/2) {}

    void init() override { spiBegin(); }
    void term() override {}

    void pinMode(uint32_t pin, uint32_t mode) override {
        if (pin >= LR_PIN_COUNT) return;
        const struct gpio_dt_spec *g = &gpios[pin];
        gpio_pin_configure(g->port, g->pin, (mode == 1) ? GPIO_OUTPUT : GPIO_INPUT);
    }
    void digitalWrite(uint32_t pin, uint32_t value) override {
        if (pin >= LR_PIN_COUNT) return;
        const struct gpio_dt_spec *g = &gpios[pin];
        gpio_pin_set_raw(g->port, g->pin, value ? 1 : 0);
    }
    uint32_t digitalRead(uint32_t pin) override {
        if (pin >= LR_PIN_COUNT) return 0;
        const struct gpio_dt_spec *g = &gpios[pin];
        return gpio_pin_get_raw(g->port, g->pin);
    }

    void attachInterrupt(uint32_t interruptNum, void (*cb)(void), uint32_t mode) override {
        if (interruptNum >= LR_PIN_COUNT) return;
        const struct gpio_dt_spec *g = &gpios[interruptNum];
        user_cb = cb;
        gpio_pin_configure(g->port, g->pin, GPIO_INPUT);   /* RadioLib doesn't pinMode the IRQ */
        if (!cb_added) {                                   /* register the callback exactly once */
            gpio_init_callback(&cb_data, gpioIsr, BIT(g->pin));
            gpio_add_callback(g->port, &cb_data);
            cb_added = true;
        }
        gpio_pin_interrupt_configure(g->port, g->pin,
            (mode == 2) ? GPIO_INT_EDGE_FALLING :
            (mode == 1) ? GPIO_INT_EDGE_RISING  : GPIO_INT_EDGE_BOTH);
    }
    void detachInterrupt(uint32_t interruptNum) override {
        if (interruptNum >= LR_PIN_COUNT) return;
        const struct gpio_dt_spec *g = &gpios[interruptNum];
        gpio_pin_interrupt_configure(g->port, g->pin, GPIO_INT_DISABLE);
        gpio_remove_callback(g->port, &cb_data);
        user_cb = nullptr;
    }

    void delay(RadioLibTime_t ms) override { k_msleep((int32_t)ms); }
    void delayMicroseconds(RadioLibTime_t us) override { k_busy_wait((uint32_t)us); }
    RadioLibTime_t millis() override { return (RadioLibTime_t)k_uptime_get(); }
    RadioLibTime_t micros() override { return (RadioLibTime_t)k_ticks_to_us_floor64(k_uptime_ticks()); }
    long pulseIn(uint32_t, uint32_t, RadioLibTime_t) override { return 0; }

    void spiBegin() override {
        spi_dev = DEVICE_DT_GET(SPI0_NODE);
        spi_cfg.frequency = 2000000;     /* 2 MHz, SPI mode 0, MSB first */
        spi_cfg.operation = SPI_OP_MODE_MASTER | SPI_WORD_SET(8) | SPI_TRANSFER_MSB;
        spi_cfg.slave = 0;
        spi_cfg.cs.gpio.port = NULL;     /* no HW CS — RadioLib toggles NSS */
    }
    void spiBeginTransaction() override {}
    void spiEndTransaction() override {}
    void spiEnd() override {}

    void spiTransfer(uint8_t *out, size_t len, uint8_t *in) override {
        struct spi_buf txb = { .buf = out, .len = len };
        struct spi_buf rxb = { .buf = in,  .len = len };
        struct spi_buf_set tx = { .buffers = &txb, .count = 1 };
        struct spi_buf_set rx = { .buffers = &rxb, .count = 1 };
        spi_transceive(spi_dev, &spi_cfg, (out ? &tx : NULL), (in ? &rx : NULL));
    }

  private:
    static void (*user_cb)(void);
    static struct gpio_callback cb_data;
    static bool cb_added;
    static void gpioIsr(const struct device *, struct gpio_callback *, uint32_t) {
        if (user_cb) user_cb();
    }

    const struct device *spi_dev = nullptr;
    struct spi_config spi_cfg = {};

    /* index by LR_PIN_*; order must match the #defines above */
    const struct gpio_dt_spec gpios[LR_PIN_COUNT] = {
        GPIO_DT_SPEC_GET(LORA0_NODE, nss_gpios),
        GPIO_DT_SPEC_GET(LORA0_NODE, dio1_gpios),
        GPIO_DT_SPEC_GET(LORA0_NODE, reset_gpios),
        GPIO_DT_SPEC_GET(LORA0_NODE, busy_gpios),
    };
};

void (*ZephyrHal::user_cb)(void) = nullptr;
struct gpio_callback ZephyrHal::cb_data;
bool ZephyrHal::cb_added = false;
```
